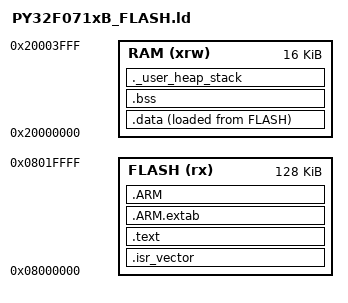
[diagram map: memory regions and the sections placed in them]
ENTRY(Reset_Handler)

MEMORY
{
  FLASH (rx)  : ORIGIN = 0x08000000, LENGTH = 128K
  RAM   (xrw) : ORIGIN = 0x20000000, LENGTH = 16K
}

_estack = ORIGIN(RAM) + LENGTH(RAM);
_Min_Heap_Size = 0x000;
_Min_Stack_Size = 0x400;

SECTIONS
{
  .isr_vector :
  {
    . = ALIGN(4);
    KEEP(*(.isr_vector))
    . = ALIGN(4);
  } > FLASH

  .text :
  {
    . = ALIGN(4);
    *(.text)
    *(.text*)
    *(.rodata)
    *(.rodata*)
    KEEP(*(.init))
    KEEP(*(.fini))
    . = ALIGN(4);
    _etext = .;
  } > FLASH

  .ARM.extab : { *(.ARM.extab* .gnu.linkonce.armextab.*) } > FLASH
  .ARM :
  {
    __exidx_start = .;
    *(.ARM.exidx*)
    __exidx_end = .;
  } > FLASH

  .data :
  {
    . = ALIGN(4);
    _sdata = .;
    *(.data)
    *(.data*)
    . = ALIGN(4);
    _edata = .;
  } > RAM AT> FLASH

  _sidata = LOADADDR(.data);

  .bss (NOLOAD) :
  {
    . = ALIGN(4);
    _sbss = .;
    __bss_start__ = _sbss;
    *(.bss)
    *(.bss*)
    *(COMMON)
    . = ALIGN(4);
    _ebss = .;
    __bss_end__ = _ebss;
  } > RAM

  ._user_heap_stack (NOLOAD) :
  {
    . = ALIGN(8);
    PROVIDE(end = .);
    PROVIDE(_end = .);
    . = . + _Min_Heap_Size;
    . = . + _Min_Stack_Size;
    . = ALIGN(8);
  } > RAM

  .ARM.attributes 0 : { *(.ARM.attributes) }
  /DISCARD/ : { *(.note*) *(.comment*) }
}
